VERSION ""

NS_ :

BS_:

BU_:

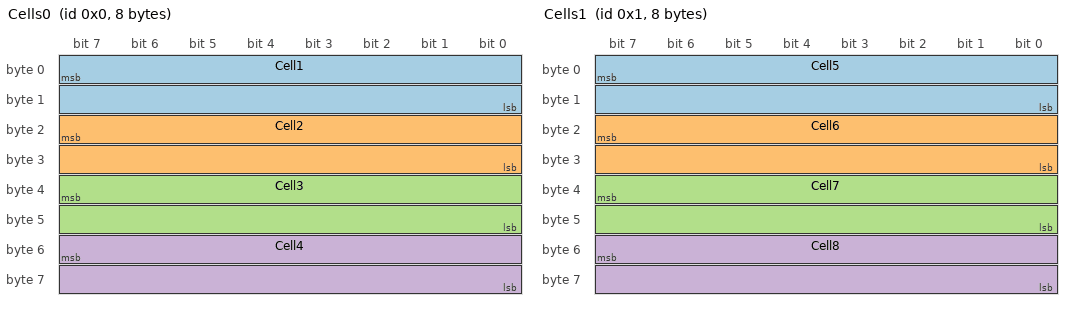
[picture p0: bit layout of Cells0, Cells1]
BO_ 0 Cells0: 8 Vector__XXX
 SG_ Cell1 : 7|16@0+ (1,0) [0|0] "V" Vector__XXX
 SG_ Cell2 : 23|16@0+ (1,0) [0|0] "V" Vector__XXX
 SG_ Cell3 : 39|16@0+ (1,0) [0|0] "V" Vector__XXX
 SG_ Cell4 : 55|16@0+ (1,0) [0|0] "V" Vector__XXX

BO_ 1 Cells1: 8 Vector__XXX
 SG_ Cell5 : 7|16@0+ (1,0) [0|0] "V" Vector__XXX
 SG_ Cell6 : 23|16@0+ (1,0) [0|0] "V" Vector__XXX
 SG_ Cell7 : 39|16@0+ (1,0) [0|0] "V" Vector__XXX
 SG_ Cell8 : 55|16@0+ (1,0) [0|0] "V" Vector__XXX

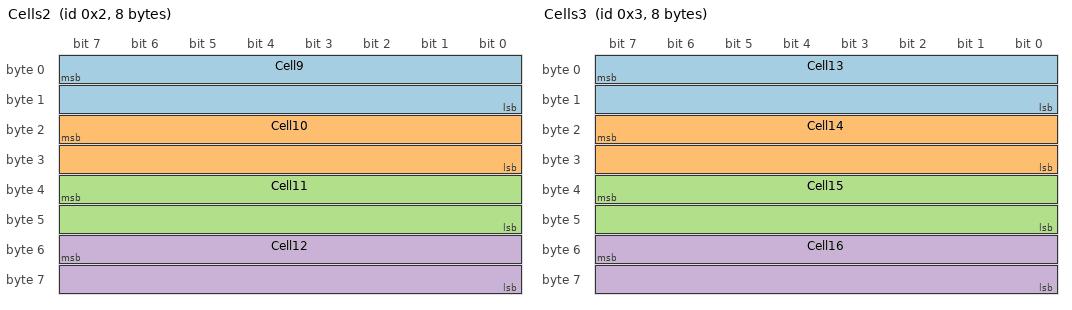
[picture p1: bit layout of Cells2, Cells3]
BO_ 2 Cells2: 8 Vector__XXX
 SG_ Cell9 : 7|16@0+ (1,0) [0|0] "V" Vector__XXX
 SG_ Cell10 : 23|16@0+ (1,0) [0|0] "V" Vector__XXX
 SG_ Cell11 : 39|16@0+ (1,0) [0|0] "V" Vector__XXX
 SG_ Cell12 : 55|16@0+ (1,0) [0|0] "V" Vector__XXX

BO_ 3 Cells3: 8 Vector__XXX
 SG_ Cell13 : 7|16@0+ (1,0) [0|0] "V" Vector__XXX
 SG_ Cell14 : 23|16@0+ (1,0) [0|0] "V" Vector__XXX
 SG_ Cell15 : 39|16@0+ (1,0) [0|0] "V" Vector__XXX
 SG_ Cell16 : 55|16@0+ (1,0) [0|0] "V" Vector__XXX

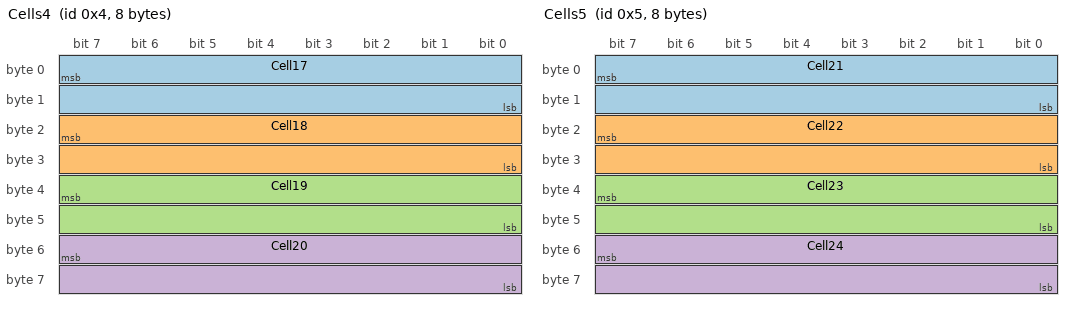
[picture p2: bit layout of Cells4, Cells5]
BO_ 4 Cells4: 8 Vector__XXX
 SG_ Cell17 : 7|16@0+ (1,0) [0|0] "V" Vector__XXX
 SG_ Cell18 : 23|16@0+ (1,0) [0|0] "V" Vector__XXX
 SG_ Cell19 : 39|16@0+ (1,0) [0|0] "V" Vector__XXX
 SG_ Cell20 : 55|16@0+ (1,0) [0|0] "V" Vector__XXX

BO_ 5 Cells5: 8 Vector__XXX
 SG_ Cell21 : 7|16@0+ (1,0) [0|0] "V" Vector__XXX
 SG_ Cell22 : 23|16@0+ (1,0) [0|0] "V" Vector__XXX
 SG_ Cell23 : 39|16@0+ (1,0) [0|0] "V" Vector__XXX
 SG_ Cell24 : 55|16@0+ (1,0) [0|0] "V" Vector__XXX

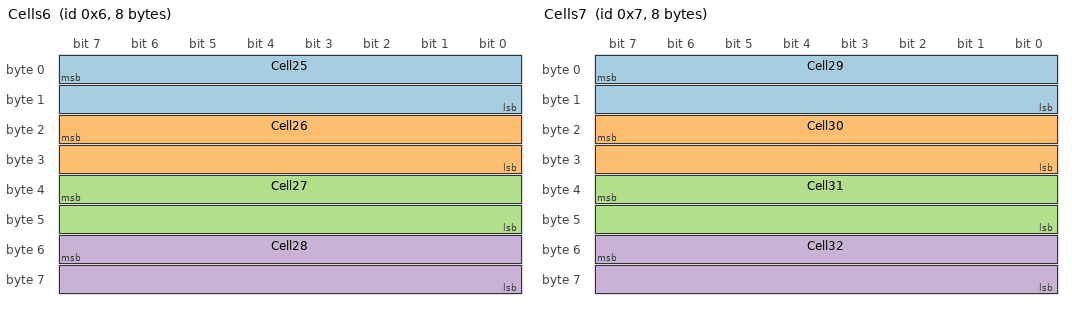
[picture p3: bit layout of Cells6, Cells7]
BO_ 6 Cells6: 8 Vector__XXX
 SG_ Cell25 : 7|16@0+ (1,0) [0|0] "V" Vector__XXX
 SG_ Cell26 : 23|16@0+ (1,0) [0|0] "V" Vector__XXX
 SG_ Cell27 : 39|16@0+ (1,0) [0|0] "V" Vector__XXX
 SG_ Cell28 : 55|16@0+ (1,0) [0|0] "V" Vector__XXX

BO_ 7 Cells7: 8 Vector__XXX
 SG_ Cell29 : 7|16@0+ (1,0) [0|0] "V" Vector__XXX
 SG_ Cell30 : 23|16@0+ (1,0) [0|0] "V" Vector__XXX
 SG_ Cell31 : 39|16@0+ (1,0) [0|0] "V" Vector__XXX
 SG_ Cell32 : 55|16@0+ (1,0) [0|0] "V" Vector__XXX

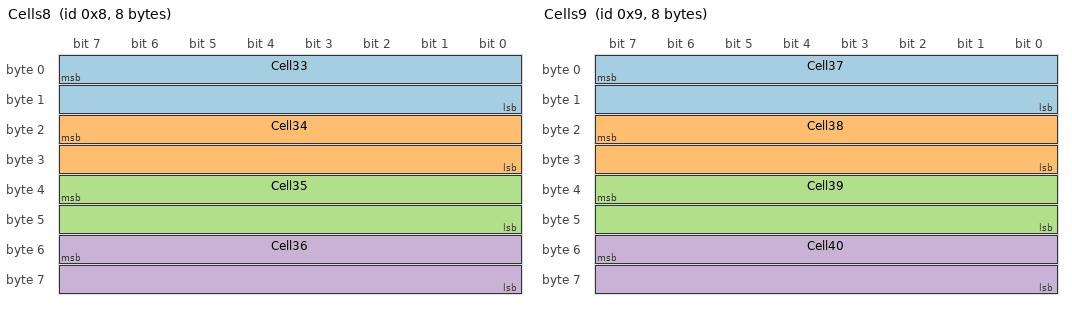
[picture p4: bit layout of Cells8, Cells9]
BO_ 8 Cells8: 8 Vector__XXX
 SG_ Cell33 : 7|16@0+ (1,0) [0|0] "V" Vector__XXX
 SG_ Cell34 : 23|16@0+ (1,0) [0|0] "V" Vector__XXX
 SG_ Cell35 : 39|16@0+ (1,0) [0|0] "V" Vector__XXX
 SG_ Cell36 : 55|16@0+ (1,0) [0|0] "V" Vector__XXX

BO_ 9 Cells9: 8 Vector__XXX
 SG_ Cell37 : 7|16@0+ (1,0) [0|0] "V" Vector__XXX
 SG_ Cell38 : 23|16@0+ (1,0) [0|0] "V" Vector__XXX
 SG_ Cell39 : 39|16@0+ (1,0) [0|0] "V" Vector__XXX
 SG_ Cell40 : 55|16@0+ (1,0) [0|0] "V" Vector__XXX

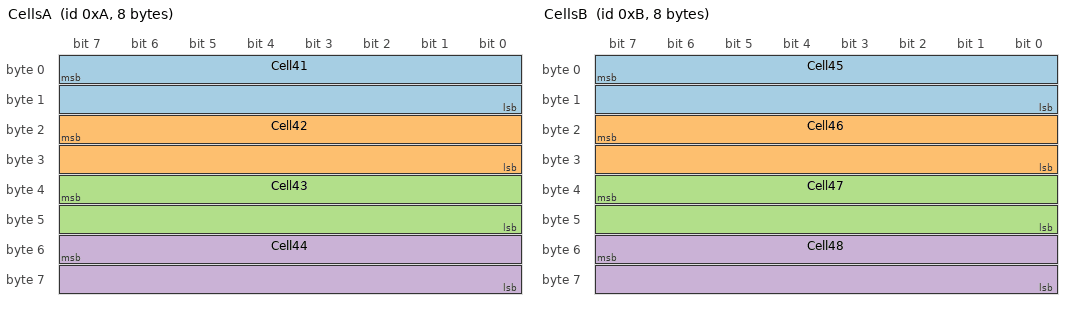
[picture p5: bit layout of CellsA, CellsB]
BO_ 10 CellsA: 8 Vector__XXX
 SG_ Cell41 : 7|16@0+ (1,0) [0|0] "V" Vector__XXX
 SG_ Cell42 : 23|16@0+ (1,0) [0|0] "V" Vector__XXX
 SG_ Cell43 : 39|16@0+ (1,0) [0|0] "V" Vector__XXX
 SG_ Cell44 : 55|16@0+ (1,0) [0|0] "V" Vector__XXX

BO_ 11 CellsB: 8 Vector__XXX
 SG_ Cell45 : 7|16@0+ (1,0) [0|0] "V" Vector__XXX
 SG_ Cell46 : 23|16@0+ (1,0) [0|0] "V" Vector__XXX
 SG_ Cell47 : 39|16@0+ (1,0) [0|0] "V" Vector__XXX
 SG_ Cell48 : 55|16@0+ (1,0) [0|0] "V" Vector__XXX

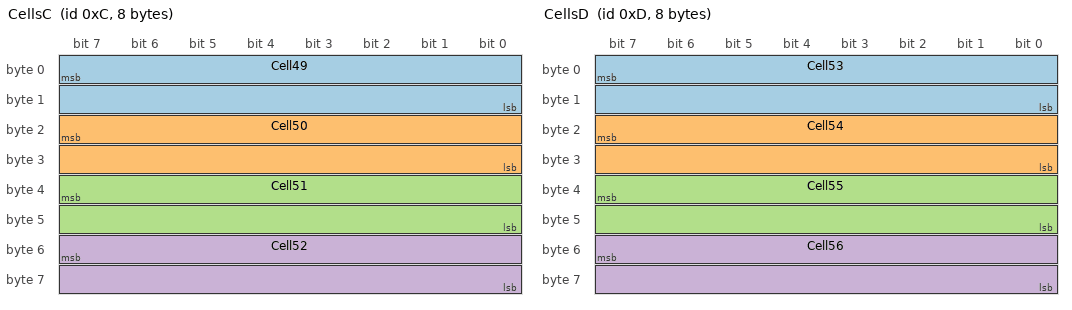
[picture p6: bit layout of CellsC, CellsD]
BO_ 12 CellsC: 8 Vector__XXX
 SG_ Cell49 : 7|16@0+ (1,0) [0|0] "V" Vector__XXX
 SG_ Cell50 : 23|16@0+ (1,0) [0|0] "V" Vector__XXX
 SG_ Cell51 : 39|16@0+ (1,0) [0|0] "V" Vector__XXX
 SG_ Cell52 : 55|16@0+ (1,0) [0|0] "V" Vector__XXX

BO_ 13 CellsD: 8 Vector__XXX
 SG_ Cell53 : 7|16@0+ (1,0) [0|0] "V" Vector__XXX
 SG_ Cell54 : 23|16@0+ (1,0) [0|0] "V" Vector__XXX
 SG_ Cell55 : 39|16@0+ (1,0) [0|0] "V" Vector__XXX
 SG_ Cell56 : 55|16@0+ (1,0) [0|0] "V" Vector__XXX

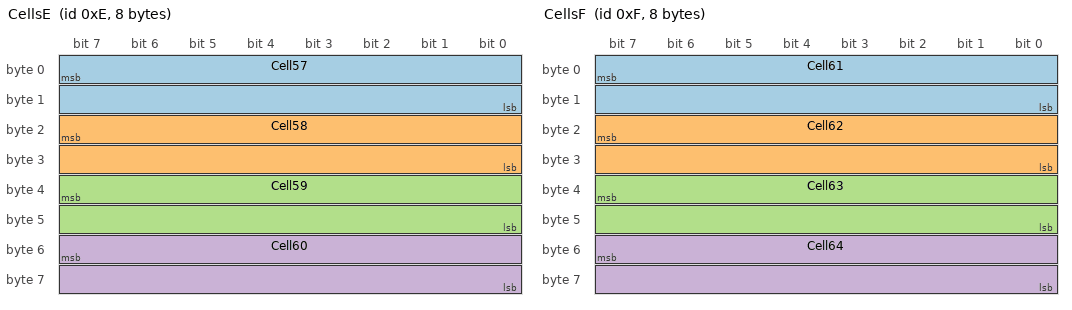
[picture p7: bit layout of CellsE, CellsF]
BO_ 14 CellsE: 8 Vector__XXX
 SG_ Cell57 : 7|16@0+ (1,0) [0|0] "V" Vector__XXX
 SG_ Cell58 : 23|16@0+ (1,0) [0|0] "V" Vector__XXX
 SG_ Cell59 : 39|16@0+ (1,0) [0|0] "V" Vector__XXX
 SG_ Cell60 : 55|16@0+ (1,0) [0|0] "V" Vector__XXX

BO_ 15 CellsF: 8 Vector__XXX
 SG_ Cell61 : 7|16@0+ (1,0) [0|0] "V" Vector__XXX
 SG_ Cell62 : 23|16@0+ (1,0) [0|0] "V" Vector__XXX
 SG_ Cell63 : 39|16@0+ (1,0) [0|0] "V" Vector__XXX
 SG_ Cell64 : 55|16@0+ (1,0) [0|0] "V" Vector__XXX

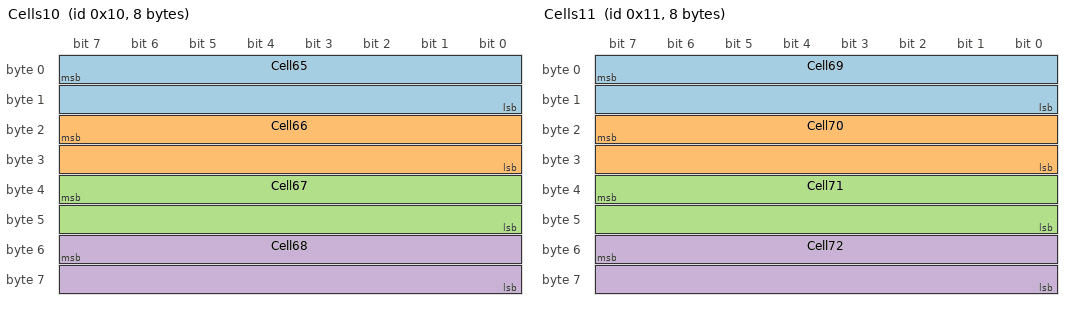
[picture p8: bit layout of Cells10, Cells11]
BO_ 16 Cells10: 8 Vector__XXX
 SG_ Cell65 : 7|16@0+ (1,0) [0|0] "V" Vector__XXX
 SG_ Cell66 : 23|16@0+ (1,0) [0|0] "V" Vector__XXX
 SG_ Cell67 : 39|16@0+ (1,0) [0|0] "V" Vector__XXX
 SG_ Cell68 : 55|16@0+ (1,0) [0|0] "V" Vector__XXX

BO_ 17 Cells11: 8 Vector__XXX
 SG_ Cell69 : 7|16@0+ (1,0) [0|0] "V" Vector__XXX
 SG_ Cell70 : 23|16@0+ (1,0) [0|0] "V" Vector__XXX
 SG_ Cell71 : 39|16@0+ (1,0) [0|0] "V" Vector__XXX
 SG_ Cell72 : 55|16@0+ (1,0) [0|0] "V" Vector__XXX

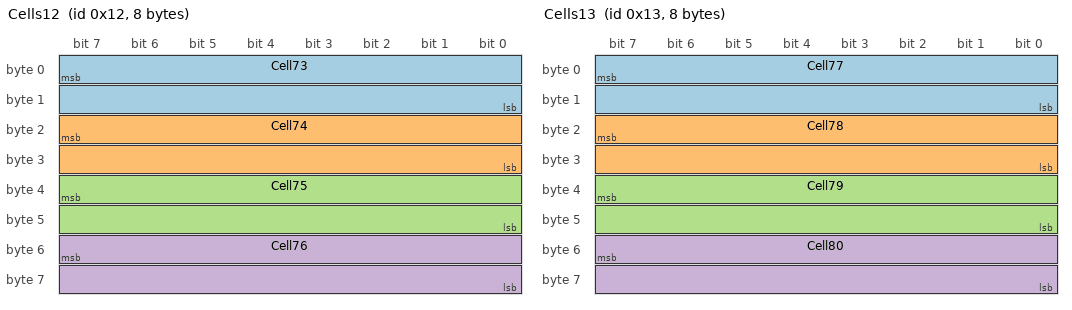
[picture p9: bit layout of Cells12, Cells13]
BO_ 18 Cells12: 8 Vector__XXX
 SG_ Cell73 : 7|16@0+ (1,0) [0|0] "V" Vector__XXX
 SG_ Cell74 : 23|16@0+ (1,0) [0|0] "V" Vector__XXX
 SG_ Cell75 : 39|16@0+ (1,0) [0|0] "V" Vector__XXX
 SG_ Cell76 : 55|16@0+ (1,0) [0|0] "V" Vector__XXX

BO_ 19 Cells13: 8 Vector__XXX
 SG_ Cell77 : 7|16@0+ (1,0) [0|0] "V" Vector__XXX
 SG_ Cell78 : 23|16@0+ (1,0) [0|0] "V" Vector__XXX
 SG_ Cell79 : 39|16@0+ (1,0) [0|0] "V" Vector__XXX
 SG_ Cell80 : 55|16@0+ (1,0) [0|0] "V" Vector__XXX

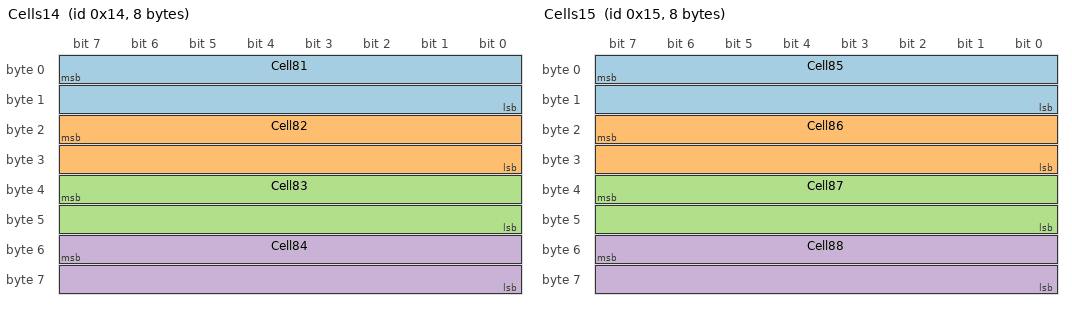
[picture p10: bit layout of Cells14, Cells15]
BO_ 20 Cells14: 8 Vector__XXX
 SG_ Cell81 : 7|16@0+ (1,0) [0|0] "V" Vector__XXX
 SG_ Cell82 : 23|16@0+ (1,0) [0|0] "V" Vector__XXX
 SG_ Cell83 : 39|16@0+ (1,0) [0|0] "V" Vector__XXX
 SG_ Cell84 : 55|16@0+ (1,0) [0|0] "V" Vector__XXX

BO_ 21 Cells15: 8 Vector__XXX
 SG_ Cell85 : 7|16@0+ (1,0) [0|0] "V" Vector__XXX
 SG_ Cell86 : 23|16@0+ (1,0) [0|0] "V" Vector__XXX
 SG_ Cell87 : 39|16@0+ (1,0) [0|0] "V" Vector__XXX
 SG_ Cell88 : 55|16@0+ (1,0) [0|0] "V" Vector__XXX

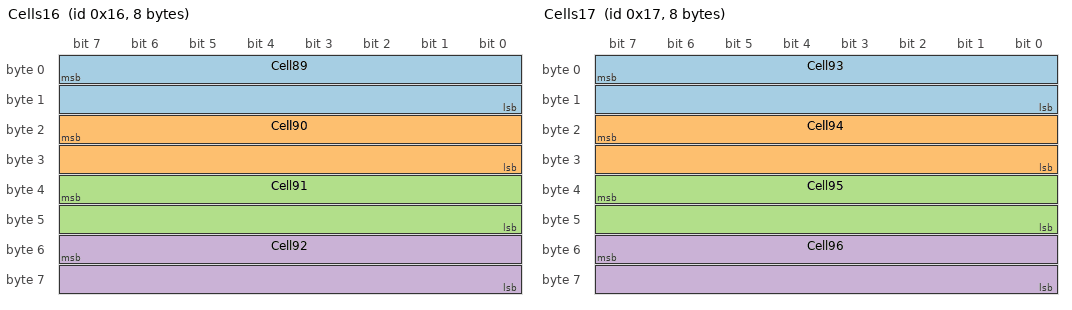
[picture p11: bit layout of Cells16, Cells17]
BO_ 22 Cells16: 8 Vector__XXX
 SG_ Cell89 : 7|16@0+ (1,0) [0|0] "V" Vector__XXX
 SG_ Cell90 : 23|16@0+ (1,0) [0|0] "V" Vector__XXX
 SG_ Cell91 : 39|16@0+ (1,0) [0|0] "V" Vector__XXX
 SG_ Cell92 : 55|16@0+ (1,0) [0|0] "V" Vector__XXX

BO_ 23 Cells17: 8 Vector__XXX
 SG_ Cell93 : 7|16@0+ (1,0) [0|0] "V" Vector__XXX
 SG_ Cell94 : 23|16@0+ (1,0) [0|0] "V" Vector__XXX
 SG_ Cell95 : 39|16@0+ (1,0) [0|0] "V" Vector__XXX
 SG_ Cell96 : 55|16@0+ (1,0) [0|0] "V" Vector__XXX

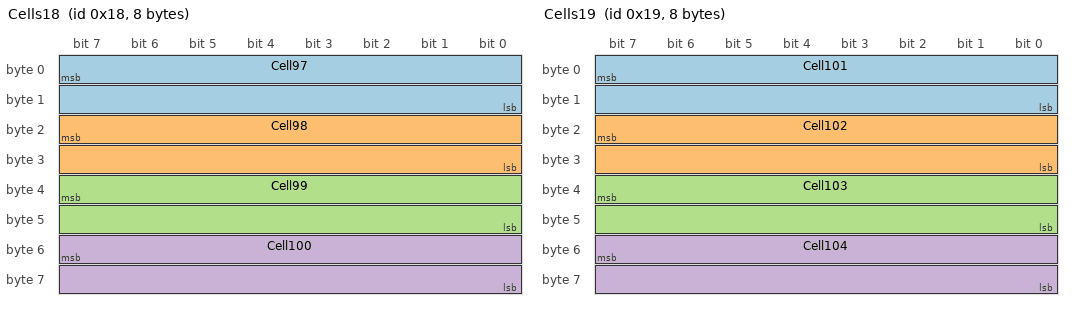
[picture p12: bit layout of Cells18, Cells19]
BO_ 24 Cells18: 8 Vector__XXX
 SG_ Cell97 : 7|16@0+ (1,0) [0|0] "V" Vector__XXX
 SG_ Cell98 : 23|16@0+ (1,0) [0|0] "V" Vector__XXX
 SG_ Cell99 : 39|16@0+ (1,0) [0|0] "V" Vector__XXX
 SG_ Cell100 : 55|16@0+ (1,0) [0|0] "V" Vector__XXX

BO_ 25 Cells19: 8 Vector__XXX
 SG_ Cell101 : 7|16@0+ (1,0) [0|0] "V" Vector__XXX
 SG_ Cell102 : 23|16@0+ (1,0) [0|0] "V" Vector__XXX
 SG_ Cell103 : 39|16@0+ (1,0) [0|0] "V" Vector__XXX
 SG_ Cell104 : 55|16@0+ (1,0) [0|0] "V" Vector__XXX

CM_ "Cell voltage frames on C CAN. Signals Cell1..Cell104 use the BMS 1-based cell numbering, matching 0x381 VmaxId/VminId directly (VmaxId N = CellN). Renumbered 2026-07-22 from a prior zero-based scheme (old CellK = new Cell(K+1)); the +1 offset documented in notes/cell-index-mapping.md no longer applies. Bit layout unchanged: 26 frames 0x000-0x019, 4x 16-bit Motorola per frame, 1 mV/bit.";
